# jpgenc_ws_bw_limiter_RATE_LIMITER_30405000h register map
Vendor: Texas Instruments
Peripheral module from a debugger description file (folder am62D).
Registers are 32-bit, read-only, reset 0x0 unless marked. A register's access mark holds for its fields unless they carry their own. Offsets are as the file gives them; lines under a group give offsets from that group; [hi:lo] are bit positions; {n}, {i} and the like mark numbered series; 'fields as' and 'values as' point back to an identical list; <NAME> marks a mode.

## rate_limiter
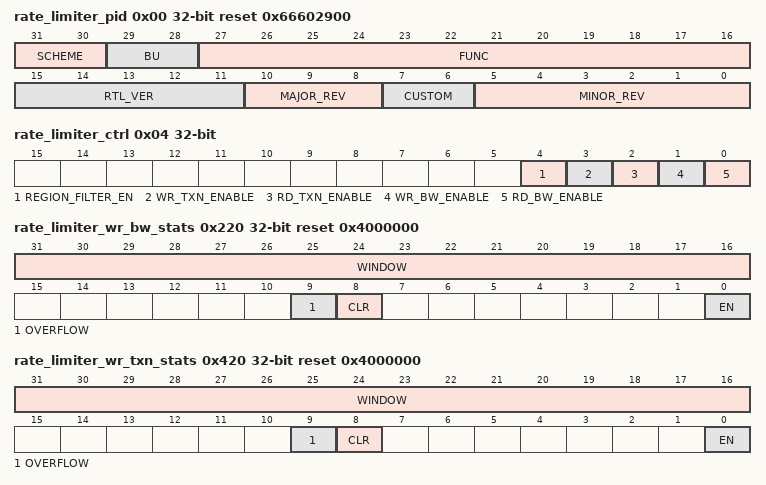
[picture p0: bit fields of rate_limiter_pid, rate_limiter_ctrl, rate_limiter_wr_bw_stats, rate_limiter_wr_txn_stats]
0x00 rate_limiter_pid reset 0x66602900 — This is the standard TI peripheral ID register that exists at address 0 in the peripheral space
  [31:30] SCHEME — PID scheme Reset Source: rst_mod_g_rst_n
  [29:28] BU — PID bu identifier Reset Source: rst_mod_g_rst_n
  [27:16] FUNC — PID function identifier Reset Source: rst_mod_g_rst_n
  [15:11] RTL_VER — PID RTL version number Reset Source: rst_mod_g_rst_n
  [10:8] MAJOR_REV — PID Major revision number Reset Source: rst_mod_g_rst_n
  [7:6] CUSTOM — PID custom Reset Source: rst_mod_g_rst_n
  [5:0] MINOR_REV — PID Minor revision number Reset Source: rst_mod_g_rst_n
0x04 rate_limiter_ctrl rw — This register controls the overall behavior of the rate limiter module
  [4] REGION_FILTER_EN — Enable the region filter, which will only apply the bandwith and transaction limits to the configured address regions Reset Source: rst_mod_g_rst_n
  [3] WR_TXN_ENABLE — Enable limiting maximum outstanding write transactions Reset Source: rst_mod_g_rst_n
  [2] RD_TXN_ENABLE — Enable limiting maximum outstanding read transactions Reset Source: rst_mod_g_rst_n
  [1] WR_BW_ENABLE — Enable write bandwidth limiting Reset Source: rst_mod_g_rst_n
  [0] RD_BW_ENABLE — Enable read bandwidth limiting Reset Source: rst_mod_g_rst_n
0x200 rate_limiter_wr_bw_cir rw — Write Bandwidth Committed Information Rate
  [31:0] CIR — Committed Information Rate Reset Source: rst_mod_g_rst_n
0x204 rate_limiter_wr_bw_pir rw — Write Bandwidth Peak Information Rate
  [31:0] PIR — Peak Information Rate Reset Source: rst_mod_g_rst_n
0x208 rate_limiter_wr_bw_burst_offset rw — Write Bandwidth Burst Offset
  [15:0] OFFSET — Burst Offset - the number of bytes before the Committed Information Rate is applied at startup or after a period of inactivity. Peak Information Rate will still apply Reset Source: rst_mod_g_rst_n
0x20C rate_limiter_wr_bw_info — Write Bandwidth State machine information. Primarly for verification purposes
  [1:0] COLOR — Write Bandwidth three-color marker output from rategen submodule Reset Source: rst_mod_g_rst_n
0x220 rate_limiter_wr_bw_stats access per field reset 0x4000000 — Write Bandwidth Statistics Control Register
  [31:16] WINDOW rw — Statistics window size. This cannot be set to 0. If 16'd0 is written, it will be set to the reset value of 16'd1024 Reset Source: rst_mod_g_rst_n
  [9] OVERFLOW ro — Statistics overflow error Reset Source: rst_mod_g_rst_n
  [8] CLR wo — Clear statistics data. Resets statistics counters at 0 Reset Source: rst_mod_g_rst_n
  [0] EN rw — Enable write bandwidth statistics Reset Source: rst_mod_g_rst_n
0x224 rate_limiter_wr_bw_stats_thrshld rw — A statistics threshold separate from the CIR and PIR
  [31:0] THRESHOLD — Write bandwidth stats threshold in bytes. Note that this is total bytes, unlike CIR and PIR. CIR and PIR are based on a rolling window, and the statistics threshold is based on a fixed window. This will still take into account DDR bytes used, so can be compared to CIR and PIR directly if the bandwidths are converted via the equations for CIR and PIR. The threshold bandwidth is programmed here as bytes per window Reset Source: rst_mod_g_rst_n
0x228 rate_limiter_wr_bw_windows_cnt — Write Bandwidth Statistics - Window Count
  [31:0] VAL — Write bandwidth window count - the number of windows elapsed since statistics collection began Reset Source: rst_mod_g_rst_n
0x22C rate_limiter_wr_bw_stats_cir — Write Bandwidth Statistics - CIR Count
  [31:0] VAL — The total number of statistics windows in which Write Commit Information Rate occurred. Note that if PIR is set to a lower value than CIR or if the burst offset feature is used, this will also count times that PIR is reached. Reset Source: rst_mod_g_rst_n
0x230 rate_limiter_wr_bw_stats_pir — Write Bandwidth Statistics - PIR Count
  [31:0] VAL — The total number of statistics windows in which Write Peak Information Rate occurred Reset Source: rst_mod_g_rst_n
0x234 rate_limiter_wr_bw_thrshld_cnt — Write Bandwidth Statistics - Threshold Count
  [31:0] VAL — The total number of statistics windows in which Write bytes transferred exceeded the statistics threshold Reset Source: rst_mod_g_rst_n
0x238 rate_limiter_wr_bytes_max — The maximum number of bytes seen in a single statitsics window. This can be compared with the window size to calculate the maximum bandwidth seen
  [31:0] VAL — Max number of bytes in a single window. This number accounts for DDR bandwidth consumed, not simply the accumulation of the packet bytecnt values across a window. The max bandwidth calculation is the total bytes value in this MMR divided by the windows size in WR_BW_STATS.window and multiplied with the interface frequency: WR_BYTES_MAX * FREQ / WR_BW_STATS.window Reset Source: rst_mod_g_rst_n
0x400 rate_limiter_wr_txn rw reset 0x40 — The maximum number of outstanding write transactions the rate limiter will allow
  [15:0] LIMIT — The maximum number of outstanding write transactions allowed. NOTE: This cannot be programmed to a zero. If a zero is written, it will default to the reset value of 16'd64, as a limit of zero outstanding transactions would hang the interface. Reset Source: rst_mod_g_rst_n
0x40C rate_limiter_wr_txn_info — Write Transaction State machine information. Primarly for verification purposes
  [6:0] OCC — Write transaction scoreboard occupancy Reset Source: rst_mod_g_rst_n
0x420 rate_limiter_wr_txn_stats access per field reset 0x4000000 — Write Transaction Stats Control Register
  [31:16] WINDOW rw — Statistics window size. This cannot be set to 0. If 16'd0 is written, it will be set to the reset value of 16'd1024 Reset Source: rst_mod_g_rst_n
  [9] OVERFLOW ro — Statistics overflow error Reset Source: rst_mod_g_rst_n
  [8] CLR wo — Clear statistics data. Resets statistics counters at 0 Reset Source: rst_mod_g_rst_n
  [0] EN rw — Enable write transaction statistics Reset Source: rst_mod_g_rst_n
0x424 rate_limiter_wr_txn_stats_thrshld rw — A statistics threshold separate from the write transaction limit
  [15:0] THRESHOLD — Write transaction statistics threshold. The threshold can be set to any value, though it will saturate at the outstanding transaction limit if it is set to a value greater than the programmed outstanding write transaction limit Reset Source: rst_mod_g_rst_n
0x428 rate_limiter_wr_txn_windows_cnt — Write Transaction Statistics - Window Count
  [31:0] VAL — Write transaction window count - the number of windows elapsed since statistics collection began Reset Source: rst_mod_g_rst_n
0x42C rate_limiter_wr_txn_limit_cnt — Write Transaction Statistics - number of windows in which the outstanding transaction limit was reached
  [31:0] VAL — The number of statistics windows in which the outstanding write transaction limit was reached Reset Source: rst_mod_g_rst_n
0x430 rate_limiter_wr_txn_threshold_cnt — Write Transaction Statistics - number of windows in which the statistics threshold was reached
  [31:0] VAL — The number of statistics windows in which the number of outstanding write transactions was greater than or equal to the threshold in WR_TXN_STATS_THRSHLD Reset Source: rst_mod_g_rst_n
0x434 rate_limiter_wr_txn_limit_total — Write Transaction Statistics - Cycles at Outstanding Write Transactions Limit
  [31:0] VAL — The total number of cycles with the write transactions outstanding at the programmed limit since statistics collection began Reset Source: rst_mod_g_rst_n
0x438 rate_limiter_wr_txn_threshold_total — Write Transaction Statistics - Cycles at the Statistics Threshold
  [31:0] VAL — The total number of cycles with write transactions outstanding greater than or equal to the statistics threshold in WR_TXN_STATS_THRSHLD since statistics collection began Reset Source: rst_mod_g_rst_n
0x43C rate_limiter_wr_txn_max — Write Transaction Statistics - Max Observed Outstanding Write Transactions
  [15:0] VAL — The maximum outstanding write transactions at any point in time, regardless of the programmed limit Reset Source: rst_mod_g_rst_n
